# haltium_cellrf register map
Vendor: Nordic Semiconductor; Series: nRFHaltium; File version: 1
CPU: CM0 r0p0, little endian, no MPU, no FPU, 2 interrupt priority bits, 33 interrupts
Registers are 32-bit, read-write, reset 0x0 unless marked. A register's access mark holds for its fields unless they carry their own. Offsets are from the block's base; [hi:lo] are bit positions; {n}, {i} and the like mark numbered series.

## GLOBAL_TSGEN — GENERIC
Base 0xBF041000
Same registers: GLOBAL_ETB 0xBF044000, GLOBAL_ETR 0xBF045000
0x00 TASKS_GENERICTASK wo — Generic event
  [0] TASKS_GENERICTASK
    1=Trigger task
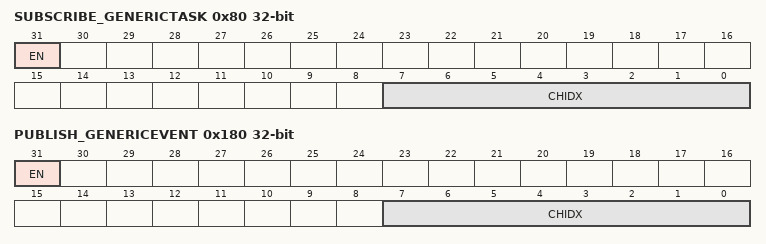
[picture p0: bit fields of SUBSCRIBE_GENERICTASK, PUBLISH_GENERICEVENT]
0x80 SUBSCRIBE_GENERICTASK — Subscribe configuration for task GENERICTASK
  [31] EN
    0=Disabled (Disable subscription); 1=Enabled (Enable subscription)
  [7:0] CHIDX — DPPI channel that task GENERICTASK will subscribe to
0x100 EVENTS_GENERICEVENT — Generic event
  [0] EVENTS_GENERICEVENT
    0=NotGenerated (Event not generated); 1=Generated (Event generated)
0x180 PUBLISH_GENERICEVENT — Publish configuration for event GENERICEVENT
  [31] EN
    0=Disabled (Disable publishing); 1=Enabled (Enable publishing)
  [7:0] CHIDX — DPPI channel that event GENERICEVENT will publish to
0x300 INTEN — Enable or disable interrupt
  [0] GENERICEVENT — Enable or disable interrupt for event GENERICEVENT
    0=Disabled; 1=Enabled
0x304 INTENSET — Enable interrupt
  [0] GENERICEVENT — Write '1' to enable interrupt for event GENERICEVENT
    on read: 0=Disabled (Read: Disabled); 1=Enabled (Read: Enabled) | on write: 1=Set (Enable)
0x308 INTENCLR — Disable interrupt
  [0] GENERICEVENT — Write '1' to disable interrupt for event GENERICEVENT
    on read: 0=Disabled (Read: Disabled); 1=Enabled (Read: Enabled) | on write: 1=Clear (Disable)

## PCGCS0 — PCGCSlave 0
Base 0x46000000
Same registers: PCGCS1 0x46004000
0x78 TRIGZEROPENALTY — Trigger zero penalty
  [0] TRIGGER
    1=Enable (Trigger zero penalty)
0x7C TRIGFULLPENALTY — Trigger full penalty
  [0] TRIGGER
    1=Enable (Trigger full penalty)
{0xC00+4i} PENALTY[{i}] (i=0..1) — Description collection: Penalty level for power/clock pair n
  [7:0] PENALTY — Penalty level
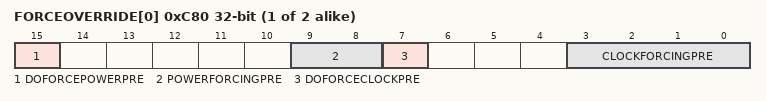
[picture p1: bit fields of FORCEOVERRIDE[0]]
{0xC80+4i} FORCEOVERRIDE[{i}] (i=0..1) — Description collection: Force override of power/clock pair n
  [15] DOFORCEPOWERPRE, [9:8] POWERFORCINGPRE, [7] DOFORCECLOCKPRE, [3:0] CLOCKFORCINGPRE

## RAMCM0 — RAM Controller 0
Base 0x46001000
Same registers: RAMCDATA 0x46002000, RAMCIPC 0x46003000, RAMCTX 0x46051000, RAMCRX 0x46052000, RAMCGNSS 0x46056000
0x500 WAITSTATES — Waitstates for read operations.
  [0] WAITSTATES — Number of waitstates for a read from the RAM.

## EGUTX — Event generator unit 0
Base 0x46022000
Same registers: EGURX 0x46033000, GLOBAL_EGU130 0x5F92D000
{0x0+4i} TASKS_TRIGGER[{i}] (i=0..15) wo — Description collection: Trigger n for triggering the corresponding TRIGGERED[n] event
  [0] TASKS_TRIGGER — Trigger n for triggering the corresponding TRIGGERED[n] event
    1=Trigger task
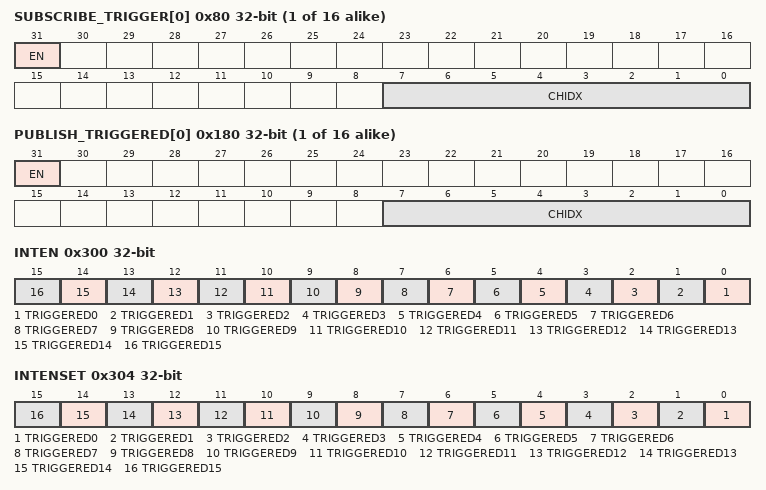
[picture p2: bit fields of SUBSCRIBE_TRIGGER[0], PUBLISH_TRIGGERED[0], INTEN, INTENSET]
{0x80+4i} SUBSCRIBE_TRIGGER[{i}] (i=0..15) — Description collection: Subscribe configuration for task TRIGGER[n]
  [31] EN
    0=Disabled (Disable subscription); 1=Enabled (Enable subscription)
  [7:0] CHIDX — DPPI channel that task TRIGGER[n] will subscribe to
{0x100+4i} EVENTS_TRIGGERED[{i}] (i=0..15) — Description collection: Event number n generated by triggering the corresponding TRIGGER[n] task
  [0] EVENTS_TRIGGERED — Event number n generated by triggering the corresponding TRIGGER[n] task
    0=NotGenerated (Event not generated); 1=Generated (Event generated)
{0x180+4i} PUBLISH_TRIGGERED[{i}] (i=0..15) — Description collection: Publish configuration for event TRIGGERED[n]
  [31] EN
    0=Disabled (Disable publishing); 1=Enabled (Enable publishing)
  [7:0] CHIDX — DPPI channel that event TRIGGERED[n] will publish to
0x300 INTEN — Enable or disable interrupt
  [all] fields
    0=Disabled; 1=Enabled
  [n] TRIGGERED{n} (n=0..15) — Enable or disable interrupt for event TRIGGERED[{n}]
0x304 INTENSET — Enable interrupt
  [all] fields
    on read: 0=Disabled (Read: Disabled); 1=Enabled (Read: Enabled) | on write: 1=Set (Enable)
  [n] TRIGGERED{n} (n=0..15) — Write '1' to enable interrupt for event TRIGGERED[{n}]
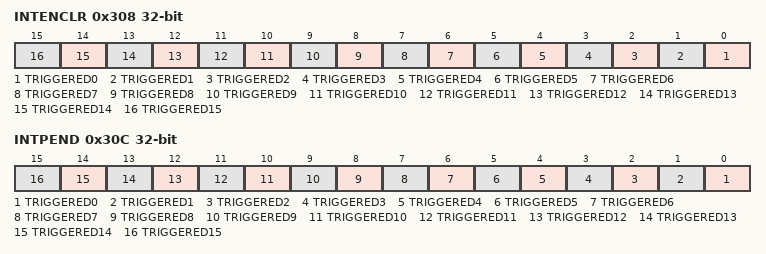
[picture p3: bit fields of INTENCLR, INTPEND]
0x308 INTENCLR — Disable interrupt
  [all] fields
    on read: 0=Disabled (Read: Disabled); 1=Enabled (Read: Enabled) | on write: 1=Clear (Disable)
  [n] TRIGGERED{n} (n=0..15) — Write '1' to disable interrupt for event TRIGGERED[{n}]
0x30C INTPEND ro — Pending interrupts
  [all] fields
    on read: 0=NotPending (Read: Not pending); 1=Pending (Read: Pending)
  [n] TRIGGERED{n} (n=0..15) — Read pending status of interrupt for event TRIGGERED[{n}]

## Notices in the file
Copyright (c) 2010 - 2021, Nordic Semiconductor ASA
All rights reserved.
Redistribution and use in source and binary forms, with or without modification,
are permitted provided that the following conditions are met:
1. Redistributions of source code must retain the above copyright notice, this
list of conditions and the following disclaimer.
2. Redistributions in binary form, except as embedded into a Nordic
Semiconductor ASA integrated circuit in a product or a software update for
such product, must reproduce the above copyright notice, this list of
conditions and the following disclaimer in the documentation and/or other
materials provided with the distribution.
3. Neither the name of Nordic Semiconductor ASA nor the names of its
contributors may be used to endorse or promote products derived from this
software without specific prior written permission.
4. This software, with or without modification, must only be used with a
Nordic Semiconductor ASA integrated circuit.
5. Any software provided in binary form under this license must not be reverse
engineered, decompiled, modified and/or disassembled.
THIS SOFTWARE IS PROVIDED BY NORDIC SEMICONDUCTOR ASA "AS IS" AND ANY EXPRESS
OR IMPLIED WARRANTIES, INCLUDING, BUT NOT LIMITED TO, THE IMPLIED WARRANTIES
OF MERCHANTABILITY, NONINFRINGEMENT, AND FITNESS FOR A PARTICULAR PURPOSE ARE
DISCLAIMED. IN NO EVENT SHALL NORDIC SEMICONDUCTOR ASA OR CONTRIBUTORS BE
LIABLE FOR ANY DIRECT, INDIRECT, INCIDENTAL, SPECIAL, EXEMPLARY, OR
CONSEQUENTIAL DAMAGES (INCLUDING, BUT NOT LIMITED TO, PROCUREMENT OF SUBSTITUTE
GOODS OR SERVICES; LOSS OF USE, DATA, OR PROFITS; OR BUSINESS INTERRUPTION)
HOWEVER CAUSED AND ON ANY THEORY OF LIABILITY, WHETHER IN CONTRACT, STRICT
LIABILITY, OR TORT (INCLUDING NEGLIGENCE OR OTHERWISE) ARISING IN ANY WAY OUT
OF THE USE OF THIS SOFTWARE, EVEN IF ADVISED OF THE POSSIBILITY OF SUCH DAMAGE.
